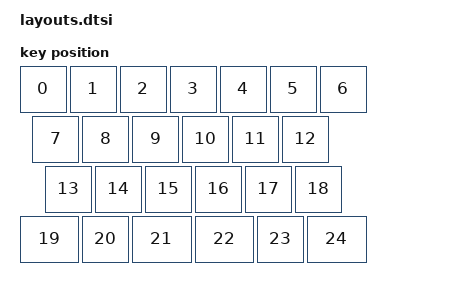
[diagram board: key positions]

#include <physical_layouts.dtsi>
/ {
    physical_layout0: physical_layout0 {
        compatible = "zmk,physical-layout";
        display-name = "Layout";
        keys
            = <&key_physical_attrs 100 100 (-50) 0 0 0 0>
			,<&key_physical_attrs 100 100 50 0 0 0 0>
			,<&key_physical_attrs 100 100 150 0 0 0 0>
			,<&key_physical_attrs 100 100 250 0 0 0 0>
			,<&key_physical_attrs 100 100 350 0 0 0 0>
			,<&key_physical_attrs 100 100 450 0 0 0 0>
			,<&key_physical_attrs 100 100 550 0 0 0 0>
			,<&key_physical_attrs 100 100 (-25) 100 0 0 0>
			,<&key_physical_attrs 100 100 75 100 0 0 0>
			,<&key_physical_attrs 100 100 175 100 0 0 0>
			,<&key_physical_attrs 100 100 275 100 0 0 0>
			,<&key_physical_attrs 100 100 375 100 0 0 0>
			,<&key_physical_attrs 100 100 475 100 0 0 0>
			,<&key_physical_attrs 100 100 0 200 0 0 0>
			,<&key_physical_attrs 100 100 100 200 0 0 0>
			,<&key_physical_attrs 100 100 200 200 0 0 0>
			,<&key_physical_attrs 100 100 300 200 0 0 0>
			,<&key_physical_attrs 100 100 400 200 0 0 0>
			,<&key_physical_attrs 100 100 500 200 0 0 0>
			,<&key_physical_attrs 125 100 (-50) 300 0 0 0>
			,<&key_physical_attrs 100 100 75 300 0 0 0>
			,<&key_physical_attrs 125 100 175 300 0 0 0>
			,<&key_physical_attrs 125 100 300 300 0 0 0>
			,<&key_physical_attrs 100 100 425 300 0 0 0>
			,<&key_physical_attrs 125 100 525 300 0 0 0>
            ;
    };
};
    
